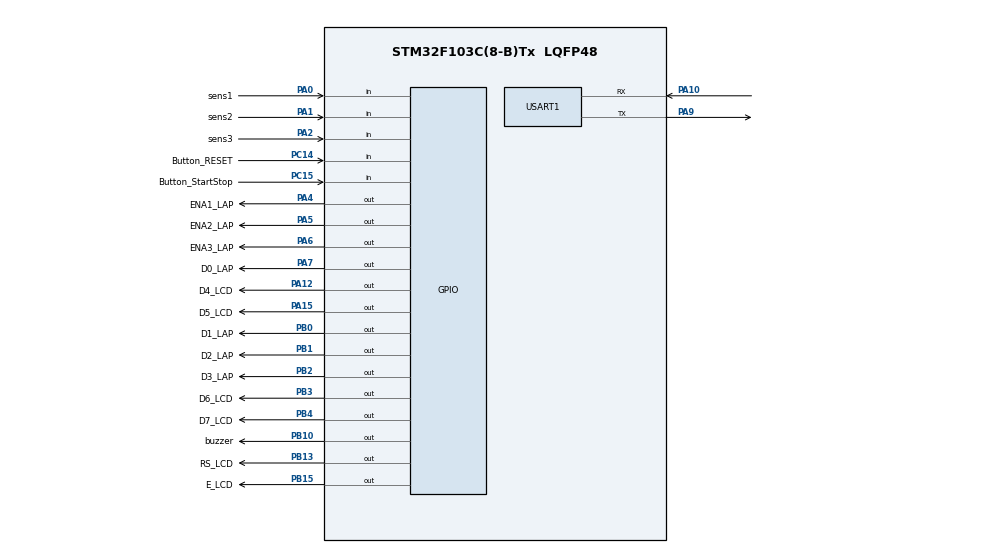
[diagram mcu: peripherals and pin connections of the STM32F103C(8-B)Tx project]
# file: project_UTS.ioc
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Mcu.Family=STM32F1
Mcu.Name=STM32F103C(8-B)Tx
Mcu.Package=LQFP48
NVIC.PriorityGroup=NVIC_PRIORITYGROUP_4
NVIC.TIM2_IRQn=true\:0\:0\:false\:false\:true\:true\:true
PA0-WKUP.GPIO_Label=sens1
PA0-WKUP.Signal=GPIO_Input
PA1.GPIO_Label=sens2
PA1.GPIO_PuPd=GPIO_NOPULL
PA1.Signal=GPIO_Input
PA10.Mode=Asynchronous
PA10.Signal=USART1_RX
PA12.GPIO_Label=D4_LCD
PA12.Signal=GPIO_Output
PA13.Mode=Serial_Wire
PA13.Signal=SYS_JTMS-SWDIO
PA14.Mode=Serial_Wire
PA14.Signal=SYS_JTCK-SWCLK
PA15.GPIO_Label=D5_LCD
PA15.Signal=GPIO_Output
PA2.GPIO_Label=sens3
PA2.Signal=GPIO_Input
PA4.GPIO_Label=ENA1_LAP
PA4.Signal=GPIO_Output
PA5.GPIO_Label=ENA2_LAP
PA5.Signal=GPIO_Output
PA6.GPIO_Label=ENA3_LAP
PA6.Signal=GPIO_Output
PA7.GPIO_Label=D0_LAP
PA7.Signal=GPIO_Output
PA9.Mode=Asynchronous
PA9.Signal=USART1_TX
PB0.GPIO_Label=D1_LAP
PB0.Signal=GPIO_Output
PB1.GPIO_Label=D2_LAP
PB1.Signal=GPIO_Output
PB10.GPIO_Label=buzzer
PB10.Signal=GPIO_Output
PB13.GPIO_Label=RS_LCD
PB13.Signal=GPIO_Output
PB15.GPIO_Label=E_LCD
PB15.Signal=GPIO_Output
PB2.GPIO_Label=D3_LAP
PB2.Signal=GPIO_Output
PB3.GPIO_Label=D6_LCD
PB3.Signal=GPIO_Output
PB4.GPIO_Label=D7_LCD
PB4.Signal=GPIO_Output
PC14-OSC32_IN.GPIO_Label=Button_RESET
PC14-OSC32_IN.GPIO_PuPd=GPIO_PULLUP
PC14-OSC32_IN.Signal=GPIO_Input
PC15-OSC32_OUT.GPIO_Label=Button_StartStop
PC15-OSC32_OUT.GPIO_PuPd=GPIO_PULLUP
PC15-OSC32_OUT.Signal=GPIO_Input
PD0-OSC_IN.Mode=HSE-External-Oscillator
PD0-OSC_IN.Signal=RCC_OSC_IN
PD1-OSC_OUT.Mode=HSE-External-Oscillator
PD1-OSC_OUT.Signal=RCC_OSC_OUT
ProjectManager.HeapSize=0x200
ProjectManager.StackSize=0x400
ProjectManager.TargetToolchain=STM32CubeIDE
RCC.AHBFreq_Value=72000000
RCC.APB1CLKDivider=RCC_HCLK_DIV2
RCC.APB1Freq_Value=36000000
RCC.APB1TimFreq_Value=72000000
RCC.APB2Freq_Value=72000000
RCC.APB2TimFreq_Value=72000000
RCC.HCLKFreq_Value=72000000
RCC.PLLMUL=RCC_PLL_MUL9
RCC.PLLSourceVirtual=RCC_PLLSOURCE_HSE
RCC.SYSCLKFreq_VALUE=72000000
RCC.SYSCLKSource=RCC_SYSCLKSOURCE_PLLCLK
RCC.USBFreq_Value=72000000
TIM2.Period=200
TIM2.Prescaler=35999
TIM3.Period=200
TIM3.Prescaler=35999
USART1.VirtualMode=VM_ASYNC
VP_TIM2_VS_ClockSourceINT.Mode=Internal
VP_TIM3_VS_ClockSourceINT.Mode=Internal
board=custom

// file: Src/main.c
/* USER CODE BEGIN Header */
/**
 ******************************************************************************
 * @file           : main.c
 * @brief          : Main program body
 ******************************************************************************
 * @attention
 *
 * <h2><center>&copy; Copyright (c) 2019 STMicroelectronics.
 * All rights reserved.</center></h2>
 *
 * This software component is licensed by ST under BSD 3-Clause license,
 * the "License"; You may not use this file except in compliance with the
 * License. You may obtain a copy of the License at:
 *                        opensource.org/licenses/BSD-3-Clause
 *
 ******************************************************************************
 */
/* USER CODE END Header */

#include "main.h"

/* USER CODE BEGIN Includes */
#include "hardwareinit.h"
#include "usart.h"
#include "timer.h"
#include "LCD_display2.h"
#include "task.h"
/* USER CODE END Includes */

TIM_HandleTypeDef htim2;
TIM_HandleTypeDef htim3;

UART_HandleTypeDef huart1;

/* USER CODE BEGIN PV */
uint16_t ms;
uint8_t s;
uint8_t m;
/* USER CODE END PV */

void SystemClock_Config(void);

int main(void)
{

	/* MCU Configuration--------------------------------------------------------*/

	/* Reset of all peripherals, Initializes the Flash interface and the Systick. */
	HAL_Init();

	/* Configure the system clock */
	SystemClock_Config();

	/* Initialize all configured peripherals */
	MX_GPIO_Init();
	MX_TIM2_Init();
	MX_TIM3_Init();
	MX_USART1_UART_Init();
	/* USER CODE BEGIN 2 */
	LCD_init();

	HAL_TIM_Base_Start_IT(&htim2);
	/* USER CODE END 2 */

	/* Infinite loop */
	/* USER CODE BEGIN WHILE */
	while (1)
	{
		//task_mulai();
		//		if (HAL_GPIO_ReadPin(Button_StartStop_GPIO_Port, Button_StartStop_Pin)==GPIO_PIN_SET){
		//			LCD_SetCursor(0, 0);
		//			LCD_print("button bisa");
		//		}
		//		else {
		//			LCD_SetCursor(0, 3);
		//			LCD_print("button tidak bisa");
		//		}
		/* USER CODE END WHILE */
//		LCD_SetCursor(0, 0);
//		LCD_print("NAGA");
	}
}

void Error_Handler(void)
{
}

/************************ (C) COPYRIGHT STMicroelectronics *****END OF FILE****/
